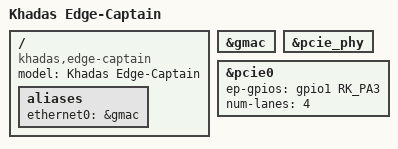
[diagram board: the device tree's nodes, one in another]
// SPDX-License-Identifier: (GPL-2.0+ OR MIT)
/*
 * Copyright (c) 2019 Shenzhen Wesion Technology Co., Ltd.
 * (https://www.khadas.com)
 */

/dts-v1/;
#include "rk3399-khadas-edge.dtsi"

/ {
	model = "Khadas Edge-Captain";
	compatible = "khadas,edge-captain", "rockchip,rk3399";

	aliases {
		ethernet0 = &gmac;
	};
};

&gmac {
	status = "okay";
};

&pcie_phy {
	status = "okay";
};

&pcie0 {
	ep-gpios = <&gpio1 RK_PA3 GPIO_ACTIVE_HIGH>;
	num-lanes = <4>;
	status = "okay";
};
